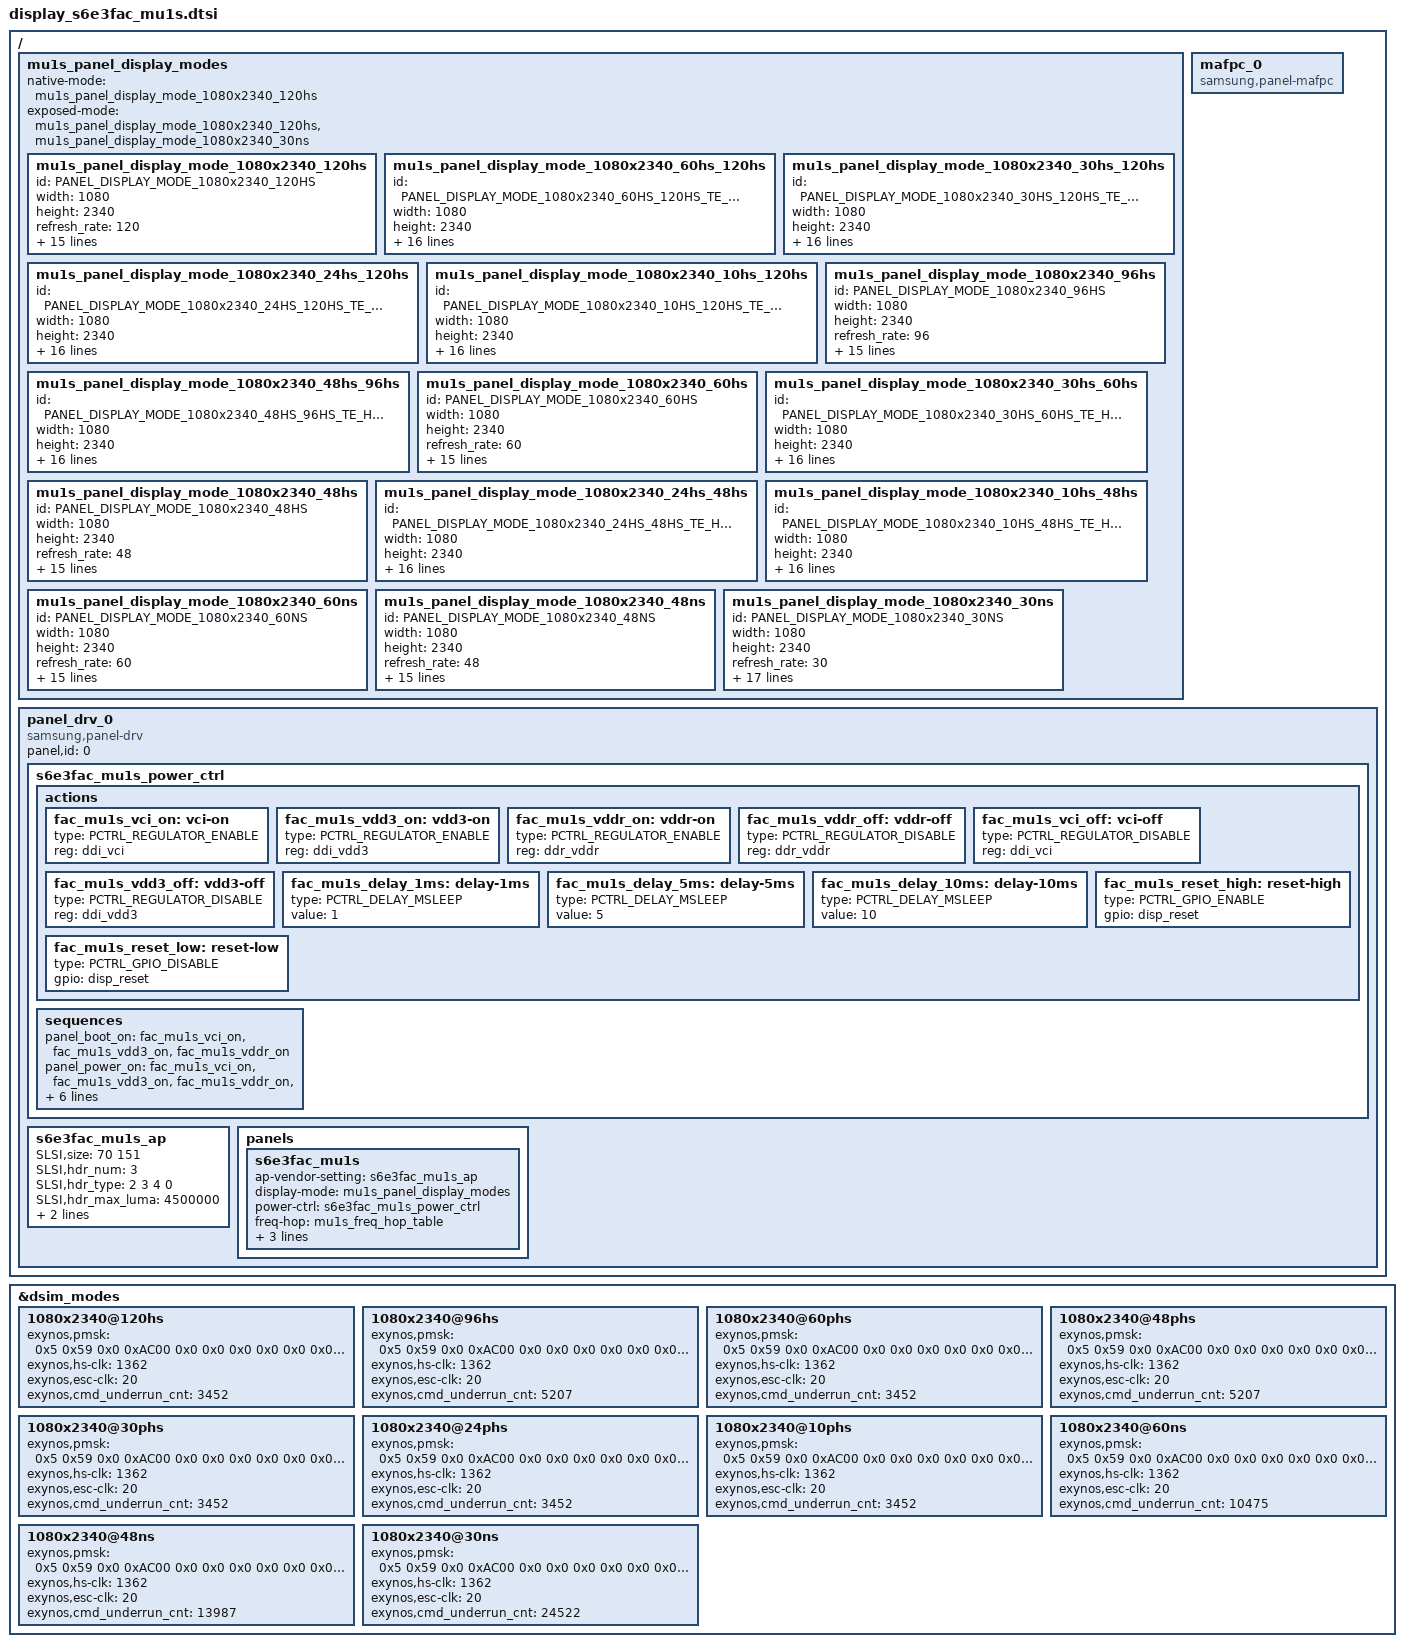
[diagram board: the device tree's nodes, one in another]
/*
 * Samsung Exynos SoC series Panel driver
 *
 * Copyright (c) 2020 Samsung Electronics Co., Ltd
 *
 * This program is free software; you can redistribute it and/or modify
 * it under the terms of the GNU General Public License version 2 as
 * published by the Free Software Foundation.
 */

#include <dt-bindings/display/panel-display.h>
#include "../display_s6e3fac_mu1s_freq_hop.dtsi"

&dsim_modes {
	/* FHD */
	1080x2340@120hs {
		exynos,pmsk = <
			0x5 0x59 0x0 0xAC00 /* p m s k */
			0x0 0x0 0x0 0x0
			0x0 0x0 0x0 0x0
			0x0 0x0
			>;
		exynos,hs-clk = <1362>;
		exynos,esc-clk = <20>;
		exynos,cmd_underrun_cnt = <3452>;
	};
	1080x2340@96hs {
		exynos,pmsk = <
			0x5 0x59 0x0 0xAC00 /* p m s k */
			0x0 0x0 0x0 0x0
			0x0 0x0 0x0 0x0
			0x0 0x0
			>;
		exynos,hs-clk = <1362>;
		exynos,esc-clk = <20>;
		exynos,cmd_underrun_cnt = <5207>;
	};
	1080x2340@60phs {
		exynos,pmsk = <
			0x5 0x59 0x0 0xAC00 /* p m s k */
			0x0 0x0 0x0 0x0
			0x0 0x0 0x0 0x0
			0x0 0x0
			>;
		exynos,hs-clk = <1362>;
		exynos,esc-clk = <20>;
		exynos,cmd_underrun_cnt = <3452>;
	};
	1080x2340@48phs {
		exynos,pmsk = <
			0x5 0x59 0x0 0xAC00 /* p m s k */
			0x0 0x0 0x0 0x0
			0x0 0x0 0x0 0x0
			0x0 0x0
			>;
		exynos,hs-clk = <1362>;
		exynos,esc-clk = <20>;
		exynos,cmd_underrun_cnt = <5207>;
	};
	1080x2340@30phs {
		exynos,pmsk = <
			0x5 0x59 0x0 0xAC00 /* p m s k */
			0x0 0x0 0x0 0x0
			0x0 0x0 0x0 0x0
			0x0 0x0
			>;
		exynos,hs-clk = <1362>;
		exynos,esc-clk = <20>;
		exynos,cmd_underrun_cnt = <3452>;
	};
	1080x2340@24phs {
		exynos,pmsk = <
			0x5 0x59 0x0 0xAC00 /* p m s k */
			0x0 0x0 0x0 0x0
			0x0 0x0 0x0 0x0
			0x0 0x0
			>;
		exynos,hs-clk = <1362>;
		exynos,esc-clk = <20>;
		exynos,cmd_underrun_cnt = <3452>;
	};
	1080x2340@10phs {
		exynos,pmsk = <
			0x5 0x59 0x0 0xAC00 /* p m s k */
			0x0 0x0 0x0 0x0
			0x0 0x0 0x0 0x0
			0x0 0x0
			>;
		exynos,hs-clk = <1362>;
		exynos,esc-clk = <20>;
		exynos,cmd_underrun_cnt = <3452>;
	};
	1080x2340@60ns {
		exynos,pmsk = <
			0x5 0x59 0x0 0xAC00 /* p m s k */
			0x0 0x0 0x0 0x0
			0x0 0x0 0x0 0x0
			0x0 0x0
			>;
		exynos,hs-clk = <1362>;
		exynos,esc-clk = <20>;
		exynos,cmd_underrun_cnt = <10475>;
	};
	1080x2340@48ns {
		exynos,pmsk = <
			0x5 0x59 0x0 0xAC00 /* p m s k */
			0x0 0x0 0x0 0x0
			0x0 0x0 0x0 0x0
			0x0 0x0
			>;
		exynos,hs-clk = <1362>;
		exynos,esc-clk = <20>;
		exynos,cmd_underrun_cnt = <13987>;
	};
	1080x2340@30ns {
		exynos,pmsk = <
			0x5 0x59 0x0 0xAC00 /* p m s k */
			0x0 0x0 0x0 0x0
			0x0 0x0 0x0 0x0
			0x0 0x0
			>;
		exynos,hs-clk = <1362>;
		exynos,esc-clk = <20>;
		exynos,cmd_underrun_cnt = <24522>;
	};
};

/ {
	fragment@panel_display_mode {
		target-path = "/";
		__overlay__ {
			mu1s_panel_display_modes:
			mu1s_panel_display_modes {
				native-mode = <&mu1s_panel_display_mode_1080x2340_120hs>;
				exposed-mode = <
					&mu1s_panel_display_mode_1080x2340_120hs
					/*
					&mu1s_panel_display_mode_1080x2340_60hs_120hs
					&mu1s_panel_display_mode_1080x2340_30hs_120hs
					&mu1s_panel_display_mode_1080x2340_24hs_120hs
					&mu1s_panel_display_mode_1080x2340_10hs_120hs
					&mu1s_panel_display_mode_1080x2340_96hs
					&mu1s_panel_display_mode_1080x2340_48hs_96hs
					&mu1s_panel_display_mode_1080x2340_60hs
					&mu1s_panel_display_mode_1080x2340_30hs_60hs
					&mu1s_panel_display_mode_1080x2340_48hs
					&mu1s_panel_display_mode_1080x2340_24hs_48hs
					&mu1s_panel_display_mode_1080x2340_10hs_48hs
					&mu1s_panel_display_mode_1080x2340_60ns
					*/
					&mu1s_panel_display_mode_1080x2340_30ns
				>;

				/* fhd */
				mu1s_panel_display_mode_1080x2340_120hs:
				mu1s_panel_display_mode_1080x2340_120hs {
					id = PANEL_DISPLAY_MODE_1080x2340_120HS;
					width = <1080>;
					height = <2340>;
					/* timing parameters */
					refresh_rate = <120>;			/* logical refresh rate */
					refresh_mode = <REFRESH_MODE_HS>;
					panel_refresh_rate = <120>;		/* panel internal refresh rate */
					panel_refresh_mode = <PANEL_REFRESH_MODE_HS>;
					panel_te_st = <0>;				/* te rising */
					panel_te_ed = <0>;				/* te falling */
					panel_te_sw_skip_count = <0>;	/* s/w te modulation */
					panel_te_hw_skip_count = <0>;	/* h/w te modulation */
					panel_h_porch = <0 0 0>;
					panel_v_porch = <28 0 0>;	/* panel vbp:16, vfp:12, but for ap vblank set vbp:16+12, vfp:0 */
					/* dsc parameters */
					dsc_en = <1>;			/* 0:Disable, 1:Enable */
					dsc_cnt = <2>;			/* used DSC count */
					dsc_slice_num = <2>;	/* count of dsc slice */
					dsc_slice_w = <540>;	/* width of dsc slice */
					dsc_slice_h = <117>;	/* height of dsc slice */
					/* dsi parameters */
					cmd_lp_ref = <3419>;
				};

				mu1s_panel_display_mode_1080x2340_60hs_120hs:
				mu1s_panel_display_mode_1080x2340_60hs_120hs {
					id = PANEL_DISPLAY_MODE_1080x2340_60HS_120HS_TE_HW_SKIP_1;
					width = <1080>;
					height = <2340>;
					/* timing parameters */
					refresh_rate = <60>;			/* logical refresh rate */
					refresh_mode = <REFRESH_MODE_PASSIVE_HS>;
					panel_refresh_rate = <120>;		/* panel internal refresh rate */
					panel_refresh_mode = <PANEL_REFRESH_MODE_HS>;
					panel_te_st = <0>;				/* te rising */
					panel_te_ed = <0>;				/* te falling */
					panel_te_sw_skip_count = <0>;	/* s/w te modulation */
					panel_te_hw_skip_count = <1>;	/* h/w te modulation */
					panel_h_porch = <0 0 0>;
					panel_v_porch = <28 0 0>;	/* panel vbp:16, vfp:12, but for ap vblank set vbp:16+12, vfp:0 */
					/* dsc parameters */
					dsc_en = <1>;			/* 0:Disable, 1:Enable */
					dsc_cnt = <2>;			/* used DSC count */
					dsc_slice_num = <2>;	/* count of dsc slice */
					dsc_slice_w = <540>;	/* width of dsc slice */
					dsc_slice_h = <117>;	/* height of dsc slice */
					/* dsi parameters */
					cmd_lp_ref = <3419>;
				};

				mu1s_panel_display_mode_1080x2340_30hs_120hs:
				mu1s_panel_display_mode_1080x2340_30hs_120hs {
					id = PANEL_DISPLAY_MODE_1080x2340_30HS_120HS_TE_HW_SKIP_3;
					width = <1080>;
					height = <2340>;
					/* timing parameters */
					refresh_rate = <30>;			/* logical refresh rate */
					refresh_mode = <REFRESH_MODE_PASSIVE_HS>;
					panel_refresh_rate = <120>;		/* panel internal refresh rate */
					panel_refresh_mode = <PANEL_REFRESH_MODE_HS>;
					panel_te_st = <0>;				/* te rising */
					panel_te_ed = <0>;				/* te falling */
					panel_te_sw_skip_count = <0>;	/* s/w te modulation */
					panel_te_hw_skip_count = <3>;	/* h/w te modulation */
					panel_h_porch = <0 0 0>;
					panel_v_porch = <28 0 0>;	/* panel vbp:16, vfp:12, but for ap vblank set vbp:16+12, vfp:0 */
					/* dsc parameters */
					dsc_en = <1>;			/* 0:Disable, 1:Enable */
					dsc_cnt = <2>;			/* used DSC count */
					dsc_slice_num = <2>;	/* count of dsc slice */
					dsc_slice_w = <540>;	/* width of dsc slice */
					dsc_slice_h = <117>;	/* height of dsc slice */
					/* dsi parameters */
					cmd_lp_ref = <3419>;
				};

				mu1s_panel_display_mode_1080x2340_24hs_120hs:
				mu1s_panel_display_mode_1080x2340_24hs_120hs {
					id = PANEL_DISPLAY_MODE_1080x2340_24HS_120HS_TE_HW_SKIP_4;
					width = <1080>;
					height = <2340>;
					/* timing parameters */
					refresh_rate = <24>;			/* logical refresh rate */
					refresh_mode = <REFRESH_MODE_PASSIVE_HS>;
					panel_refresh_rate = <120>;		/* panel internal refresh rate */
					panel_refresh_mode = <PANEL_REFRESH_MODE_HS>;
					panel_te_st = <0>;				/* te rising */
					panel_te_ed = <0>;				/* te falling */
					panel_te_sw_skip_count = <0>;	/* s/w te modulation */
					panel_te_hw_skip_count = <4>;	/* h/w te modulation */
					panel_h_porch = <0 0 0>;
					panel_v_porch = <28 0 0>;	/* panel vbp:16, vfp:12, but for ap vblank set vbp:16+12, vfp:0 */
					/* dsc parameters */
					dsc_en = <1>;			/* 0:Disable, 1:Enable */
					dsc_cnt = <2>;			/* used DSC count */
					dsc_slice_num = <2>;	/* count of dsc slice */
					dsc_slice_w = <540>;	/* width of dsc slice */
					dsc_slice_h = <117>;	/* height of dsc slice */
					/* dsi parameters */
					cmd_lp_ref = <3419>;
				};

				mu1s_panel_display_mode_1080x2340_10hs_120hs:
				mu1s_panel_display_mode_1080x2340_10hs_120hs {
					id = PANEL_DISPLAY_MODE_1080x2340_10HS_120HS_TE_HW_SKIP_11;
					width = <1080>;
					height = <2340>;
					/* timing parameters */
					refresh_rate = <10>;			/* logical refresh rate */
					refresh_mode = <REFRESH_MODE_PASSIVE_HS>;
					panel_refresh_rate = <120>;		/* panel internal refresh rate */
					panel_refresh_mode = <PANEL_REFRESH_MODE_HS>;
					panel_te_st = <0>;				/* te rising */
					panel_te_ed = <0>;				/* te falling */
					panel_te_sw_skip_count = <0>;	/* s/w te modulation */
					panel_te_hw_skip_count = <11>;	/* h/w te modulation */
					panel_h_porch = <0 0 0>;
					panel_v_porch = <28 0 0>;	/* panel vbp:16, vfp:12, but for ap vblank set vbp:16+12, vfp:0 */
					/* dsc parameters */
					dsc_en = <1>;			/* 0:Disable, 1:Enable */
					dsc_cnt = <2>;			/* used DSC count */
					dsc_slice_num = <2>;	/* count of dsc slice */
					dsc_slice_w = <540>;	/* width of dsc slice */
					dsc_slice_h = <117>;	/* height of dsc slice */
					/* dsi parameters */
					cmd_lp_ref = <3419>;
				};

				mu1s_panel_display_mode_1080x2340_96hs:
				mu1s_panel_display_mode_1080x2340_96hs {
					id = PANEL_DISPLAY_MODE_1080x2340_96HS;
					width = <1080>;
					height = <2340>;
					/* timing parameters */
					refresh_rate = <96>;			/* logical refresh rate */
					refresh_mode = <REFRESH_MODE_HS>;
					panel_refresh_rate = <96>;		/* panel internal refresh rate */
					panel_refresh_mode = <PANEL_REFRESH_MODE_HS>;
					panel_te_st = <0>;				/* te rising */
					panel_te_ed = <0>;				/* te falling */
					panel_te_sw_skip_count = <0>;	/* s/w te modulation */
					panel_te_hw_skip_count = <0>;	/* h/w te modulation */
					panel_h_porch = <0 0 0>;
					panel_v_porch = <620 0 0>;	/* panel vbp:16, vfp:604, but for ap vblank set vbp:620, vfp:0 */
					/* dsc parameters */
					dsc_en = <1>;			/* 0:Disable, 1:Enable */
					dsc_cnt = <2>;			/* used DSC count */
					dsc_slice_num = <2>;	/* count of dsc slice */
					dsc_slice_w = <540>;	/* width of dsc slice */
					dsc_slice_h = <117>;	/* height of dsc slice */
					/* dsi parameters */
					cmd_lp_ref = <5175>;
				};

				mu1s_panel_display_mode_1080x2340_48hs_96hs:
				mu1s_panel_display_mode_1080x2340_48hs_96hs {
					id = PANEL_DISPLAY_MODE_1080x2340_48HS_96HS_TE_HW_SKIP_1;
					width = <1080>;
					height = <2340>;
					/* timing parameters */
					refresh_rate = <48>;			/* logical refresh rate */
					refresh_mode = <REFRESH_MODE_PASSIVE_HS>;
					panel_refresh_rate = <96>;		/* panel internal refresh rate */
					panel_refresh_mode = <PANEL_REFRESH_MODE_HS>;
					panel_te_st = <0>;				/* te rising */
					panel_te_ed = <0>;				/* te falling */
					panel_te_sw_skip_count = <0>;	/* s/w te modulation */
					panel_te_hw_skip_count = <1>;	/* h/w te modulation */
					panel_h_porch = <0 0 0>;
					panel_v_porch = <620 0 0>;	/* panel vbp:16, vfp:604, but for ap vblank set vbp:620, vfp:0 */
					/* dsc parameters */
					dsc_en = <1>;			/* 0:Disable, 1:Enable */
					dsc_cnt = <2>;			/* used DSC count */
					dsc_slice_num = <2>;	/* count of dsc slice */
					dsc_slice_w = <540>;	/* width of dsc slice */
					dsc_slice_h = <117>;	/* height of dsc slice */
					/* dsi parameters */
					cmd_lp_ref = <5175>;
				};

				mu1s_panel_display_mode_1080x2340_60hs:
				mu1s_panel_display_mode_1080x2340_60hs {
					id = PANEL_DISPLAY_MODE_1080x2340_60HS;
					width = <1080>;
					height = <2340>;
					/* timing parameters */
					refresh_rate = <60>;			/* logical refresh rate */
					refresh_mode = <REFRESH_MODE_HS>;
					panel_refresh_rate = <60>;		/* panel internal refresh rate */
					panel_refresh_mode = <PANEL_REFRESH_MODE_HS>;
					panel_te_st = <0>;				/* te rising */
					panel_te_ed = <0>;				/* te falling */
					panel_te_sw_skip_count = <0>;	/* s/w te modulation */
					panel_te_hw_skip_count = <0>;	/* h/w te modulation */
					panel_h_porch = <0 0 0>;
					panel_v_porch = <2396 0 0>;	/* panel vbp:16, vfp:2380, but for ap vblank set vbp:2396, vfp:0 */
					/* dsc parameters */
					dsc_en = <1>;			/* 0:Disable, 1:Enable */
					dsc_cnt = <2>;			/* used DSC count */
					dsc_slice_num = <2>;	/* count of dsc slice */
					dsc_slice_w = <540>;	/* width of dsc slice */
					dsc_slice_h = <117>;	/* height of dsc slice */
					/* dsi parameters */
					cmd_lp_ref = <10442>;
				};

				mu1s_panel_display_mode_1080x2340_30hs_60hs:
				mu1s_panel_display_mode_1080x2340_30hs_60hs {
					id = PANEL_DISPLAY_MODE_1080x2340_30HS_60HS_TE_HW_SKIP_1;
					width = <1080>;
					height = <2340>;
					/* timing parameters */
					refresh_rate = <30>;			/* logical refresh rate */
					refresh_mode = <REFRESH_MODE_HS>;
					panel_refresh_rate = <60>;		/* panel internal refresh rate */
					panel_refresh_mode = <PANEL_REFRESH_MODE_HS>;
					panel_te_st = <0>;				/* te rising */
					panel_te_ed = <0>;				/* te falling */
					panel_te_sw_skip_count = <0>;	/* s/w te modulation */
					panel_te_hw_skip_count = <1>;	/* h/w te modulation */
					panel_h_porch = <0 0 0>;
					panel_v_porch = <1200 1196 0>;	/* panel vbp:16, vfp:2380, but for ap vblank set vbp:16+1184, vfp:2380-1184 */
					/* dsc parameters */
					dsc_en = <1>;			/* 0:Disable, 1:Enable */
					dsc_cnt = <2>;			/* used DSC count */
					dsc_slice_num = <2>;	/* count of dsc slice */
					dsc_slice_w = <540>;	/* width of dsc slice */
					dsc_slice_h = <117>;	/* height of dsc slice */
					/* dsi parameters */
					cmd_lp_ref = <6931>;	/* underrun count for hsclk=1362, bts.fps=80 */
				};

				mu1s_panel_display_mode_1080x2340_48hs:
				mu1s_panel_display_mode_1080x2340_48hs {
					id = PANEL_DISPLAY_MODE_1080x2340_48HS;
					width = <1080>;
					height = <2340>;
					/* timing parameters */
					refresh_rate = <48>;			/* logical refresh rate */
					refresh_mode = <REFRESH_MODE_HS>;
					panel_refresh_rate = <48>;		/* panel internal refresh rate */
					panel_refresh_mode = <PANEL_REFRESH_MODE_HS>;
					panel_te_st = <0>;				/* te rising */
					panel_te_ed = <0>;				/* te falling */
					panel_te_sw_skip_count = <0>;	/* s/w te modulation */
					panel_te_hw_skip_count = <0>;	/* h/w te modulation */
					panel_h_porch = <0 0 0>;
					panel_v_porch = <3576 0 0>;	/* panel vbp:16, vfp:3564, but for ap vblank set vbp:16+3564, vfp:0 */
					/* dsc parameters */
					dsc_en = <1>;			/* 0:Disable, 1:Enable */
					dsc_cnt = <2>;			/* used DSC count */
					dsc_slice_num = <2>;	/* count of dsc slice */
					dsc_slice_w = <540>;	/* width of dsc slice */
					dsc_slice_h = <117>;	/* height of dsc slice */
					/* dsi parameters */
					cmd_lp_ref = <13954>;
				};

				mu1s_panel_display_mode_1080x2340_24hs_48hs:
				mu1s_panel_display_mode_1080x2340_24hs_48hs {
					id = PANEL_DISPLAY_MODE_1080x2340_24HS_48HS_TE_HW_SKIP_1;
					width = <1080>;
					height = <2340>;
					/* timing parameters */
					refresh_rate = <24>;			/* logical refresh rate */
					refresh_mode = <REFRESH_MODE_HS>;
					panel_refresh_rate = <48>;		/* panel internal refresh rate */
					panel_refresh_mode = <PANEL_REFRESH_MODE_HS>;
					panel_te_st = <0>;				/* te rising */
					panel_te_ed = <0>;				/* te falling */
					panel_te_sw_skip_count = <0>;	/* s/w te modulation */
					panel_te_hw_skip_count = <1>;	/* h/w te modulation */
					panel_h_porch = <0 0 0>;
					panel_v_porch = <1496 2084 0>;	/* panel vbp:16, vfp:3564, but for ap vblank set vbp:16+1480, vfp:3564-1480 */
					/* dsc parameters */
					dsc_en = <1>;			/* 0:Disable, 1:Enable */
					dsc_cnt = <2>;			/* used DSC count */
					dsc_slice_num = <2>;	/* count of dsc slice */
					dsc_slice_w = <540>;	/* width of dsc slice */
					dsc_slice_h = <117>;	/* height of dsc slice */
					/* dsi parameters */
					cmd_lp_ref = <7785>;	/* underrun count for hsclk=1362, bts.fps=74 */
				};

				mu1s_panel_display_mode_1080x2340_10hs_48hs:
				mu1s_panel_display_mode_1080x2340_10hs_48hs {
					id = PANEL_DISPLAY_MODE_1080x2340_10HS_48HS_TE_HW_SKIP_4;
					width = <1080>;
					height = <2340>;
					/* timing parameters */
					refresh_rate = <10>;			/* logical refresh rate */
					refresh_mode = <REFRESH_MODE_HS>;
					panel_refresh_rate = <48>;		/* panel internal refresh rate */
					panel_refresh_mode = <PANEL_REFRESH_MODE_HS>;
					panel_te_st = <0>;				/* te rising */
					panel_te_ed = <0>;				/* te falling */
					panel_te_sw_skip_count = <0>;	/* s/w te modulation */
					panel_te_hw_skip_count = <4>;	/* h/w te modulation */
					panel_h_porch = <0 0 0>;
					panel_v_porch = <1496 2084 0>;	/* panel vbp:16, vfp:3564, but for ap vblank set vbp:16+1480, vfp:3564-1480 */
					/* dsc parameters */
					dsc_en = <1>;			/* 0:Disable, 1:Enable */
					dsc_cnt = <2>;			/* used DSC count */
					dsc_slice_num = <2>;	/* count of dsc slice */
					dsc_slice_w = <540>;	/* width of dsc slice */
					dsc_slice_h = <117>;	/* height of dsc slice */
					/* dsi parameters */
					cmd_lp_ref = <7785>;	/* underrun count for hsclk=1362, bts.fps=74 */
				};

				mu1s_panel_display_mode_1080x2340_60ns:
				mu1s_panel_display_mode_1080x2340_60ns {
					id = PANEL_DISPLAY_MODE_1080x2340_60NS;
					width = <1080>;
					height = <2340>;
					/* timing parameters */
					refresh_rate = <60>;			/* logical refresh rate */
					refresh_mode = <REFRESH_MODE_NS>;
					panel_refresh_rate = <60>;		/* panel internal refresh rate */
					panel_refresh_mode = <PANEL_REFRESH_MODE_NS>;
					panel_te_st = <0>;				/* te rising */
					panel_te_ed = <0>;				/* te falling */
					panel_te_sw_skip_count = <0>;	/* s/w te modulation */
					panel_te_hw_skip_count = <0>;	/* h/w te modulation */
					panel_h_porch = <0 0 0>;
					panel_v_porch = <28 0 0>;	/* panel vbp:16, vfp:12, but for ap vblank set vbp:16+12, vfp:0 */
					/* dsc parameters */
					dsc_en = <1>;			/* 0:Disable, 1:Enable */
					dsc_cnt = <2>;			/* used DSC count */
					dsc_slice_num = <2>;	/* count of dsc slice */
					dsc_slice_w = <540>;	/* width of dsc slice */
					dsc_slice_h = <117>;	/* height of dsc slice */
					/* dsi parameters */
					cmd_lp_ref = <10442>;
				};

				mu1s_panel_display_mode_1080x2340_48ns:
				mu1s_panel_display_mode_1080x2340_48ns {
					id = PANEL_DISPLAY_MODE_1080x2340_48NS;
					width = <1080>;
					height = <2340>;
					/* timing parameters */
					refresh_rate = <48>;			/* logical refresh rate */
					refresh_mode = <REFRESH_MODE_NS>;
					panel_refresh_rate = <48>;		/* panel internal refresh rate */
					panel_refresh_mode = <PANEL_REFRESH_MODE_NS>;
					panel_te_st = <0>;				/* te rising */
					panel_te_ed = <0>;				/* te falling */
					panel_te_sw_skip_count = <0>;	/* s/w te modulation */
					panel_te_hw_skip_count = <0>;	/* h/w te modulation */
					panel_h_porch = <0 0 0>;
					panel_v_porch = <620 0 0>;	/* panel vbp:16, vfp:604, but for ap vblank set vbp:620, vfp:0 */
					/* dsc parameters */
					dsc_en = <1>;			/* 0:Disable, 1:Enable */
					dsc_cnt = <2>;			/* used DSC count */
					dsc_slice_num = <2>;	/* count of dsc slice */
					dsc_slice_w = <540>;	/* width of dsc slice */
					dsc_slice_h = <117>;	/* height of dsc slice */
					/* dsi parameters */
					cmd_lp_ref = <13954>;
				};

				mu1s_panel_display_mode_1080x2340_30ns:
				mu1s_panel_display_mode_1080x2340_30ns {
					id = PANEL_DISPLAY_MODE_1080x2340_30NS;
					width = <1080>;
					height = <2340>;
					/* timing parameters */
					refresh_rate = <30>;			/* logical refresh rate */
					refresh_mode = <REFRESH_MODE_NS>;
					panel_refresh_rate = <30>;		/* panel internal refresh rate */
					panel_refresh_mode = <PANEL_REFRESH_MODE_NS>;
					panel_te_st = <0>;				/* te rising */
					panel_te_ed = <0>;				/* te falling */
					panel_te_sw_skip_count = <0>;	/* s/w te modulation */
					panel_te_hw_skip_count = <0>;	/* h/w te modulation */
					panel_h_porch = <0 0 0>;
					panel_v_porch = <28 0 0>;	/* panel vbp:16, vfp:12, but for ap vblank set vbp:16+12, vfp:0 */
					/* dsc parameters */
					dsc_en = <1>;			/* 0:Disable, 1:Enable */
					dsc_cnt = <2>;			/* used DSC count */
					dsc_slice_num = <2>;	/* count of dsc slice */
					dsc_slice_w = <540>;	/* width of dsc slice */
					dsc_slice_h = <117>;	/* height of dsc slice */
					/* dsi parameters */
					cmd_lp_ref = <24489>;
					doze_mode;
					panel_lp_mode;
				};
			};
		};
	};
};

/ {
	fragment@panel_drv {
		target-path = "/";
		__overlay__ {
			mafpc_0: mafpc_0 {
					 compatible = "samsung,panel-mafpc";
					 status = "okay";
			};

			panel_drv_0: panel_drv_0 {
				status = "okay";
				compatible = "samsung,panel-drv";
				panel,id = <0>;

				s6e3fac_mu1s_power_ctrl: s6e3fac_mu1s_power_ctrl {
					actions {
						fac_mu1s_vci_on: vci-on {
							type = <PCTRL_REGULATOR_ENABLE>;
							reg = <&ddi_vci>;
						};
						fac_mu1s_vdd3_on: vdd3-on {
							type = <PCTRL_REGULATOR_ENABLE>;
							reg = <&ddi_vdd3>;
						};
						fac_mu1s_vddr_on: vddr-on {
							type = <PCTRL_REGULATOR_ENABLE>;
							reg = <&ddr_vddr>;
						};
						fac_mu1s_vddr_off: vddr-off {
							type = <PCTRL_REGULATOR_DISABLE>;
							reg = <&ddr_vddr>;
						};
						fac_mu1s_vci_off: vci-off {
							type = <PCTRL_REGULATOR_DISABLE>;
							reg = <&ddi_vci>;
						};
						fac_mu1s_vdd3_off: vdd3-off {
							type = <PCTRL_REGULATOR_DISABLE>;
							reg = <&ddi_vdd3>;
						};
						fac_mu1s_delay_1ms: delay-1ms {
							type = <PCTRL_DELAY_MSLEEP>;
							value = <1>;
						};
						fac_mu1s_delay_5ms: delay-5ms {
							type = <PCTRL_DELAY_MSLEEP>;
							value = <5>;
						};
						fac_mu1s_delay_10ms: delay-10ms {
							type = <PCTRL_DELAY_MSLEEP>;
							value = <10>;
						};
						fac_mu1s_reset_high: reset-high {
							type = <PCTRL_GPIO_ENABLE>;
							gpio = <&disp_reset>;
						};
						fac_mu1s_reset_low: reset-low {
							type = <PCTRL_GPIO_DISABLE>;
							gpio = <&disp_reset>;
						};
					};
					sequences {
						panel_boot_on = <&fac_mu1s_vci_on &fac_mu1s_vdd3_on &fac_mu1s_vddr_on>;
						panel_power_on = <&fac_mu1s_vci_on &fac_mu1s_vdd3_on &fac_mu1s_vddr_on &fac_mu1s_delay_10ms &fac_mu1s_reset_high &fac_mu1s_delay_5ms>;
						panel_power_off = <&fac_mu1s_reset_low &fac_mu1s_delay_1ms &fac_mu1s_vddr_off &fac_mu1s_delay_1ms &fac_mu1s_vdd3_off &fac_mu1s_vci_off>;
					};
				};

				s6e3fac_mu1s_ap:s6e3fac_mu1s_ap {
					/* S.LSI */
					SLSI,size = <70 151>;
					SLSI,hdr_num = <3>;			/* max: 4 */
					SLSI,hdr_type = <2 3 4 0>;		/* 1: DOLBY_VISION, 2: HDR10, 3: HLG */
					SLSI,hdr_max_luma = <4500000>;	/* 450 */
					SLSI,hdr_max_avg_luma = <1200000>;	/* 120 */
					SLSI,hdr_min_luma = <5>;		/* 0.0005 */
				};

				panels {
					s6e3fac_mu1s: s6e3fac_mu1s {
						ap-vendor-setting = <&s6e3fac_mu1s_ap>;
						display-mode = <&mu1s_panel_display_modes>;
						power-ctrl = <&s6e3fac_mu1s_power_ctrl>;
						freq-hop = <&mu1s_freq_hop_table>;
						dqe-suffix = "s6e3fac_mu1s";
						id-mask = <
							PANEL_ID(0x810220) PANEL_MASK(0xFFFFF0) /* DM1 */
							PANEL_ID(0x811620) PANEL_MASK(0xFFFFF0) /* DM2 */
						>;
					};
				};
			};
		};
	};
};

